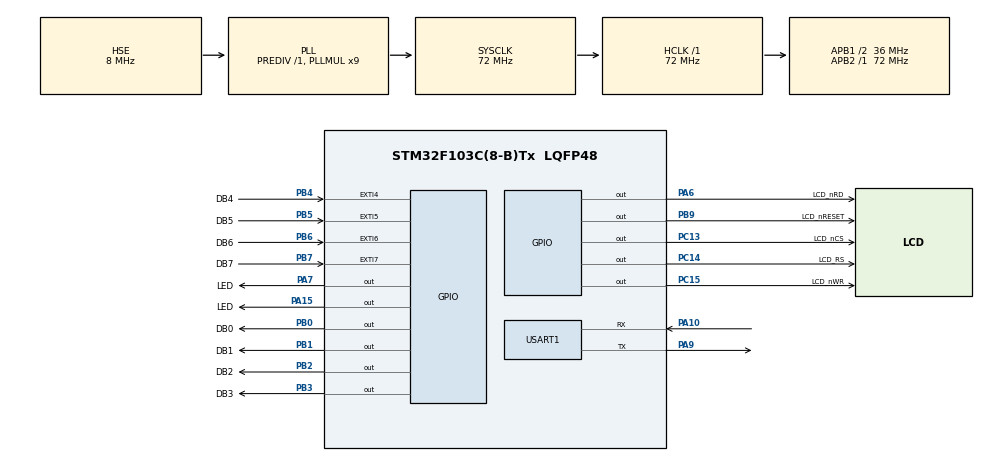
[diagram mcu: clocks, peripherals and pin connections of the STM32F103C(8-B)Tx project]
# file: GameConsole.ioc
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Mcu.Family=STM32F1
Mcu.Name=STM32F103C(8-B)Tx
Mcu.Package=LQFP48
NVIC.EXTI4_IRQn=true\:0\:0\:false\:false\:true\:true\:true\:true
NVIC.EXTI9_5_IRQn=true\:0\:0\:false\:false\:true\:true\:true\:true
NVIC.PriorityGroup=NVIC_PRIORITYGROUP_4
NVIC.TIM1_UP_IRQn=true\:0\:0\:false\:false\:true\:true\:true\:true
PA10.Mode=Asynchronous
PA10.Signal=USART1_RX
PA13.Mode=Serial_Wire
PA13.Signal=SYS_JTMS-SWDIO
PA14.Mode=Serial_Wire
PA14.Signal=SYS_JTCK-SWCLK
PA15.GPIO_Label=LED
PA15.Signal=GPIO_Output
PA6.GPIO_Label=LCD_nRD
PA6.Signal=GPIO_Output
PA7.GPIO_Label=LED
PA7.Signal=GPIO_Output
PA9.Mode=Asynchronous
PA9.Signal=USART1_TX
PB0.GPIO_Label=DB0
PB0.Signal=GPIO_Output
PB1.GPIO_Label=DB1
PB1.Signal=GPIO_Output
PB2.GPIO_Label=DB2
PB2.Signal=GPIO_Output
PB3.GPIO_Label=DB3
PB3.Signal=GPIO_Output
PB4.GPIO_Label=DB4
PB4.GPIO_ModeDefaultEXTI=GPIO_MODE_IT_RISING_FALLING
PB4.Signal=GPXTI4
PB5.GPIO_Label=DB5
PB5.GPIO_ModeDefaultEXTI=GPIO_MODE_IT_RISING_FALLING
PB5.Signal=GPXTI5
PB6.GPIO_Label=DB6
PB6.GPIO_ModeDefaultEXTI=GPIO_MODE_IT_RISING_FALLING
PB6.Signal=GPXTI6
PB7.GPIO_Label=DB7
PB7.GPIO_ModeDefaultEXTI=GPIO_MODE_IT_RISING_FALLING
PB7.Signal=GPXTI7
PB9.GPIO_Label=LCD_nRESET
PB9.Signal=GPIO_Output
PC13-TAMPER-RTC.GPIO_Label=LCD_nCS
PC13-TAMPER-RTC.Signal=GPIO_Output
PC14-OSC32_IN.GPIO_Label=LCD_RS
PC14-OSC32_IN.Signal=GPIO_Output
PC15-OSC32_OUT.GPIO_Label=LCD_nWR
PC15-OSC32_OUT.Signal=GPIO_Output
PD0-OSC_IN.Mode=HSE-External-Oscillator
PD0-OSC_IN.Signal=RCC_OSC_IN
PD1-OSC_OUT.Mode=HSE-External-Oscillator
PD1-OSC_OUT.Signal=RCC_OSC_OUT
ProjectManager.HeapSize=0x200
ProjectManager.StackSize=0x400
ProjectManager.TargetToolchain=STM32CubeIDE
RCC.AHBFreq_Value=72000000
RCC.APB1CLKDivider=RCC_HCLK_DIV2
RCC.APB1Freq_Value=36000000
RCC.APB1TimFreq_Value=72000000
RCC.APB2Freq_Value=72000000
RCC.APB2TimFreq_Value=72000000
RCC.HCLKFreq_Value=72000000
RCC.PLLMUL=RCC_PLL_MUL9
RCC.PLLSourceVirtual=RCC_PLLSOURCE_HSE
RCC.SYSCLKFreq_VALUE=72000000
RCC.SYSCLKSource=RCC_SYSCLKSOURCE_PLLCLK
RCC.USBFreq_Value=72000000
TIM1.Period=999
TIM1.Prescaler=71
USART1.VirtualMode=VM_ASYNC
VP_TIM1_VS_ClockSourceINT.Mode=Internal
board=custom

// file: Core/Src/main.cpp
/* USER CODE BEGIN Header */
/**
  ******************************************************************************
  * @file           : main.c
  * @brief          : Main program body
  ******************************************************************************
  * @attention
  *
  * Copyright (c) 2023 STMicroelectronics.
  * All rights reserved.
  *
  * This software is licensed under terms that can be found in the LICENSE file
  * in the root directory of this software component.
  * If no LICENSE file comes with this software, it is provided AS-IS.
  *
  ******************************************************************************
  */
/* USER CODE END Header */
#include "main.h"

/* USER CODE BEGIN Includes */
#include "MainThread.hpp"
/* USER CODE END Includes */

TIM_HandleTypeDef htim1;

UART_HandleTypeDef huart1;

void SystemClock_Config(void);
static void MX_GPIO_Init(void);
static void MX_TIM1_Init(void);
static void MX_USART1_UART_Init(void);

int main(void)
{

  /* MCU Configuration--------------------------------------------------------*/

  /* Reset of all peripherals, Initializes the Flash interface and the Systick. */
  HAL_Init();

  /* Configure the system clock */
  SystemClock_Config();

  /* Initialize all configured peripherals */
  MX_GPIO_Init();
  MX_TIM1_Init();
  MX_USART1_UART_Init();

  /* Infinite loop */
  /* USER CODE BEGIN WHILE */
  while (1)
  {
	  MainThread();
    /* USER CODE END WHILE */

  }
}

void SystemClock_Config(void)
{
  RCC_OscInitTypeDef RCC_OscInitStruct = {0};
  RCC_ClkInitTypeDef RCC_ClkInitStruct = {0};

  /** Initializes the RCC Oscillators according to the specified parameters
  * in the RCC_OscInitTypeDef structure.
  */
  RCC_OscInitStruct.OscillatorType = RCC_OSCILLATORTYPE_HSE;
  RCC_OscInitStruct.HSEState = RCC_HSE_ON;
  RCC_OscInitStruct.HSEPredivValue = RCC_HSE_PREDIV_DIV1;
  RCC_OscInitStruct.HSIState = RCC_HSI_ON;
  RCC_OscInitStruct.PLL.PLLState = RCC_PLL_ON;
  RCC_OscInitStruct.PLL.PLLSource = RCC_PLLSOURCE_HSE;
  RCC_OscInitStruct.PLL.PLLMUL = RCC_PLL_MUL9;
  if (HAL_RCC_OscConfig(&RCC_OscInitStruct) != HAL_OK)
  {
    Error_Handler();
  }

  /** Initializes the CPU, AHB and APB buses clocks
  */
  RCC_ClkInitStruct.ClockType = RCC_CLOCKTYPE_HCLK|RCC_CLOCKTYPE_SYSCLK
                              |RCC_CLOCKTYPE_PCLK1|RCC_CLOCKTYPE_PCLK2;
  RCC_ClkInitStruct.SYSCLKSource = RCC_SYSCLKSOURCE_PLLCLK;
  RCC_ClkInitStruct.AHBCLKDivider = RCC_SYSCLK_DIV1;
  RCC_ClkInitStruct.APB1CLKDivider = RCC_HCLK_DIV2;
  RCC_ClkInitStruct.APB2CLKDivider = RCC_HCLK_DIV1;

  if (HAL_RCC_ClockConfig(&RCC_ClkInitStruct, FLASH_LATENCY_2) != HAL_OK)
  {
    Error_Handler();
  }
}

static void MX_TIM1_Init(void)
{

  TIM_ClockConfigTypeDef sClockSourceConfig = {0};
  TIM_MasterConfigTypeDef sMasterConfig = {0};

  htim1.Instance = TIM1;
  htim1.Init.Prescaler = 71;
  htim1.Init.CounterMode = TIM_COUNTERMODE_UP;
  htim1.Init.Period = 999;
  htim1.Init.ClockDivision = TIM_CLOCKDIVISION_DIV1;
  htim1.Init.RepetitionCounter = 0;
  htim1.Init.AutoReloadPreload = TIM_AUTORELOAD_PRELOAD_DISABLE;
  if (HAL_TIM_Base_Init(&htim1) != HAL_OK)
  {
    Error_Handler();
  }
  sClockSourceConfig.ClockSource = TIM_CLOCKSOURCE_INTERNAL;
  if (HAL_TIM_ConfigClockSource(&htim1, &sClockSourceConfig) != HAL_OK)
  {
    Error_Handler();
  }
  sMasterConfig.MasterOutputTrigger = TIM_TRGO_RESET;
  sMasterConfig.MasterSlaveMode = TIM_MASTERSLAVEMODE_DISABLE;
  if (HAL_TIMEx_MasterConfigSynchronization(&htim1, &sMasterConfig) != HAL_OK)
  {
    Error_Handler();
  }

}

static void MX_USART1_UART_Init(void)
{

  huart1.Instance = USART1;
  huart1.Init.BaudRate = 115200;
  huart1.Init.WordLength = UART_WORDLENGTH_8B;
  huart1.Init.StopBits = UART_STOPBITS_1;
  huart1.Init.Parity = UART_PARITY_NONE;
  huart1.Init.Mode = UART_MODE_TX_RX;
  huart1.Init.HwFlowCtl = UART_HWCONTROL_NONE;
  huart1.Init.OverSampling = UART_OVERSAMPLING_16;
  if (HAL_UART_Init(&huart1) != HAL_OK)
  {
    Error_Handler();
  }

}

static void MX_GPIO_Init(void)
{
  GPIO_InitTypeDef GPIO_InitStruct = {0};

  /* GPIO Ports Clock Enable */
  __HAL_RCC_GPIOC_CLK_ENABLE();
  __HAL_RCC_GPIOD_CLK_ENABLE();
  __HAL_RCC_GPIOA_CLK_ENABLE();
  __HAL_RCC_GPIOB_CLK_ENABLE();

  /*Configure GPIO pin Output Level */
  HAL_GPIO_WritePin(GPIOC, LCD_nCS_Pin|LCD_RS_Pin|LCD_nWR_Pin, GPIO_PIN_RESET);

  /*Configure GPIO pin Output Level */
  HAL_GPIO_WritePin(GPIOA, LCD_nRD_Pin|LED_Pin|LEDA15_Pin, GPIO_PIN_RESET);

  /*Configure GPIO pin Output Level */
  HAL_GPIO_WritePin(GPIOB, DB0_Pin|DB1_Pin|DB2_Pin|DB3_Pin
                          |LCD_nRESET_Pin, GPIO_PIN_RESET);

  /*Configure GPIO pins : LCD_nCS_Pin LCD_RS_Pin LCD_nWR_Pin */
  GPIO_InitStruct.Pin = LCD_nCS_Pin|LCD_RS_Pin|LCD_nWR_Pin;
  GPIO_InitStruct.Mode = GPIO_MODE_OUTPUT_PP;
  GPIO_InitStruct.Pull = GPIO_NOPULL;
  GPIO_InitStruct.Speed = GPIO_SPEED_FREQ_LOW;
  HAL_GPIO_Init(GPIOC, &GPIO_InitStruct);

  /*Configure GPIO pins : LCD_nRD_Pin LED_Pin LEDA15_Pin */
  GPIO_InitStruct.Pin = LCD_nRD_Pin|LED_Pin|LEDA15_Pin;
  GPIO_InitStruct.Mode = GPIO_MODE_OUTPUT_PP;
  GPIO_InitStruct.Pull = GPIO_NOPULL;
  GPIO_InitStruct.Speed = GPIO_SPEED_FREQ_LOW;
  HAL_GPIO_Init(GPIOA, &GPIO_InitStruct);

  /*Configure GPIO pins : DB0_Pin DB1_Pin DB2_Pin DB3_Pin
                           LCD_nRESET_Pin */
  GPIO_InitStruct.Pin = DB0_Pin|DB1_Pin|DB2_Pin|DB3_Pin
                          |LCD_nRESET_Pin;
  GPIO_InitStruct.Mode = GPIO_MODE_OUTPUT_PP;
  GPIO_InitStruct.Pull = GPIO_NOPULL;
  GPIO_InitStruct.Speed = GPIO_SPEED_FREQ_LOW;
  HAL_GPIO_Init(GPIOB, &GPIO_InitStruct);

  /*Configure GPIO pins : DB4_Pin DB5_Pin DB6_Pin DB7_Pin */
  GPIO_InitStruct.Pin = DB4_Pin|DB5_Pin|DB6_Pin|DB7_Pin;
  GPIO_InitStruct.Mode = GPIO_MODE_IT_RISING_FALLING;
  GPIO_InitStruct.Pull = GPIO_NOPULL;
  HAL_GPIO_Init(GPIOB, &GPIO_InitStruct);

  /* EXTI interrupt init*/
  HAL_NVIC_SetPriority(EXTI4_IRQn, 0, 0);
  HAL_NVIC_EnableIRQ(EXTI4_IRQn);

  HAL_NVIC_SetPriority(EXTI9_5_IRQn, 0, 0);
  HAL_NVIC_EnableIRQ(EXTI9_5_IRQn);

}

void Error_Handler(void)
{
  __disable_irq();
  while (1)
  {
  }
}
